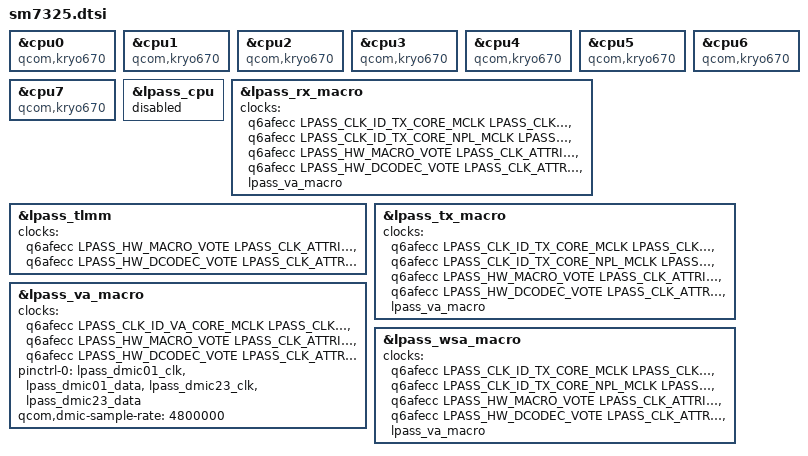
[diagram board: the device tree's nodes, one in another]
// SPDX-License-Identifier: BSD-3-Clause
/*
 * Copyright (c) 2024, Eugene Lepshy <fekz115@gmail.com>
 * Copyright (c) 2024, Danila Tikhonov <danila@jiaxyga.com>
 */

#include "sc7280.dtsi"

#include <dt-bindings/sound/qcom,q6dsp-lpass-ports.h>

/* SM7325 uses Kryo 670 */
&cpu0 { compatible = "qcom,kryo670"; };
&cpu1 { compatible = "qcom,kryo670"; };
&cpu2 { compatible = "qcom,kryo670"; };
&cpu3 { compatible = "qcom,kryo670"; };
&cpu4 { compatible = "qcom,kryo670"; };
&cpu5 { compatible = "qcom,kryo670"; };
&cpu6 { compatible = "qcom,kryo670"; };
&cpu7 { compatible = "qcom,kryo670"; };

&lpass_cpu { status = "disabled"; };

&lpass_rx_macro {
	/delete-property/ power-domains;
	/delete-property/ power-domain-names;
	clocks = <&q6afecc LPASS_CLK_ID_TX_CORE_MCLK LPASS_CLK_ATTRIBUTE_COUPLE_NO>,
		 <&q6afecc LPASS_CLK_ID_TX_CORE_NPL_MCLK  LPASS_CLK_ATTRIBUTE_COUPLE_NO>,
		 <&q6afecc LPASS_HW_MACRO_VOTE LPASS_CLK_ATTRIBUTE_COUPLE_NO>,
		 <&q6afecc LPASS_HW_DCODEC_VOTE LPASS_CLK_ATTRIBUTE_COUPLE_NO>,
		 <&lpass_va_macro>;
	clock-names = "mclk",
		      "npl",
		      "macro",
		      "dcodec",
		      "fsgen";
};

&lpass_tlmm {
	clocks = <&q6afecc LPASS_HW_MACRO_VOTE LPASS_CLK_ATTRIBUTE_COUPLE_NO>,
		 <&q6afecc LPASS_HW_DCODEC_VOTE LPASS_CLK_ATTRIBUTE_COUPLE_NO>;
	clock-names = "core",
		      "audio";
};

&lpass_tx_macro {
	/delete-property/ power-domains;
	/delete-property/ power-domain-names;
	clocks = <&q6afecc LPASS_CLK_ID_TX_CORE_MCLK LPASS_CLK_ATTRIBUTE_COUPLE_NO>,
		 <&q6afecc LPASS_CLK_ID_TX_CORE_NPL_MCLK LPASS_CLK_ATTRIBUTE_COUPLE_NO>,
		 <&q6afecc LPASS_HW_MACRO_VOTE LPASS_CLK_ATTRIBUTE_COUPLE_NO>,
		 <&q6afecc LPASS_HW_DCODEC_VOTE LPASS_CLK_ATTRIBUTE_COUPLE_NO>,
		 <&lpass_va_macro>;
	clock-names = "mclk",
		      "npl",
		      "macro",
		      "dcodec",
		      "fsgen";
};

&lpass_va_macro {
	/delete-property/ power-domains;
	/delete-property/ power-domain-names;
	clocks = <&q6afecc LPASS_CLK_ID_VA_CORE_MCLK LPASS_CLK_ATTRIBUTE_COUPLE_NO>,
		 <&q6afecc LPASS_HW_MACRO_VOTE LPASS_CLK_ATTRIBUTE_COUPLE_NO>,
		 <&q6afecc LPASS_HW_DCODEC_VOTE LPASS_CLK_ATTRIBUTE_COUPLE_NO>;
	clock-names = "mclk",
		      "macro",
		      "dcodec";

	pinctrl-0 = <&lpass_dmic01_clk>, <&lpass_dmic01_data>,
		    <&lpass_dmic23_clk>, <&lpass_dmic23_data>;
	pinctrl-names = "default";

	qcom,dmic-sample-rate = <4800000>;
};

&lpass_wsa_macro {
	clocks = <&q6afecc LPASS_CLK_ID_TX_CORE_MCLK LPASS_CLK_ATTRIBUTE_COUPLE_NO>,
		 <&q6afecc LPASS_CLK_ID_TX_CORE_NPL_MCLK LPASS_CLK_ATTRIBUTE_COUPLE_NO>,
		 <&q6afecc LPASS_HW_MACRO_VOTE LPASS_CLK_ATTRIBUTE_COUPLE_NO>,
		 <&q6afecc LPASS_HW_DCODEC_VOTE LPASS_CLK_ATTRIBUTE_COUPLE_NO>,
		 <&lpass_va_macro>;
	clock-names = "mclk",
		      "npl",
		      "macro",
		      "dcodec",
		      "fsgen";
};
